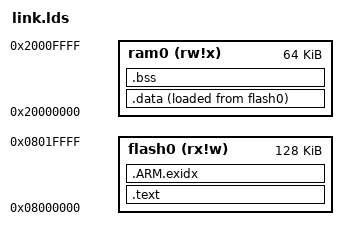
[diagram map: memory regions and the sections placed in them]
/*
 * This file was auto-generated by microzig
 *
 * Target CPU:  ARM Cortex-M4
 * Target Chip: STM32F407
 */

ENTRY(microzig_main);

MEMORY
{
  flash0    (rx!w) : ORIGIN = 0x08000000, LENGTH = 0x0020000
  ram0      (rw!x) : ORIGIN = 0x20000000, LENGTH = 0x00010000
}

SECTIONS
{
  .text :
  {
    KEEP(*(microzig_flash_start))
    *(.text*)
  } > flash0

  .ARM.exidx : {
    *(.ARM.exidx* .gnu.linkonce.armexidx.*)
  } >flash0

  .data :
  {
    microzig_data_start = .;
    *(.rodata*)
    *(.data*)
    KEEP(*(fal))
    microzig_data_end = .;
  } > ram0 AT> flash0

  .bss (NOLOAD) :
  {
    microzig_bss_start = .;
    *(.bss*)
    microzig_bss_end = .;
    . = ALIGN(4);
    microzig_stack_start = .;
    . = . + 0x8000;
    . = ALIGN(4);
    microzig_stack_end = .;
  } > ram0

  microzig_data_load_start = LOADADDR(.data);
}
